# YTM32B1ME1 register map
Vendor: YTMicro; File version: 1.0
CPU: CM33 r0p4, little endian, MPU, FPU, 2 interrupt priority bits
Registers are 32-bit, read-write, reset 0x0 unless marked. A register's access mark holds for its fields unless they carry their own. Offsets are from the block's base; [hi:lo] are bit positions; {n}, {i} and the like mark numbered series; 'fields as' and 'values as' point back to an identical list.

## SCU — System Clock Unit of Microcontroller
Base 0x401F0000; register names take the prefix SCU_
0x00 CLKS — The register contains clock select bits.
  [1:0] CLKSRCSEL — System Clock Source selection bits.
    0=Select FIRC as system clock source; 1=Select PLL as system clock source; 2=Select FXOSC as system clock source; 3=Select SIRC as system clock source
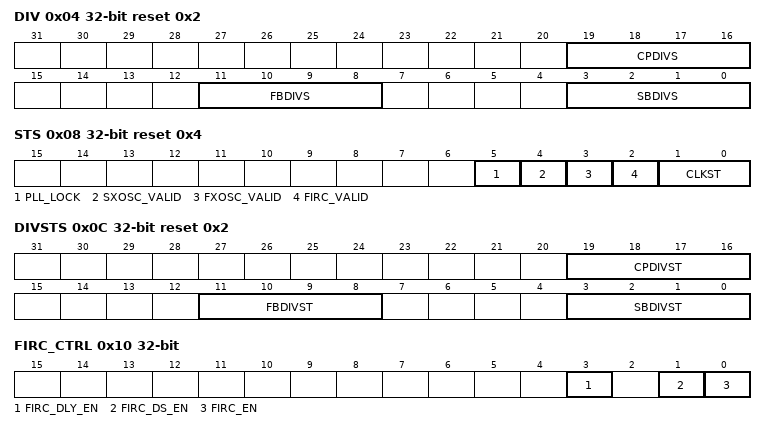
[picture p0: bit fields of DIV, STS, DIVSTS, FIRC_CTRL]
0x04 DIV reset 0x2 — System Clock Divider
  [all] fields
    {v}=Divide by {v+1} (v=0..15)
  [19:16] CPDIVS — Core Platform Clock Divider Value
  [11:8] FBDIVS — Fast Bus Clock Divider Value
  [3:0] SBDIVS — Slow Bus Clock Divider Value
0x08 STS ro reset 0x4 — System Clock Unit Status register
  [5] PLL_LOCK
    0=PLL unlocked; 1=PLL locked
  [4] SXOSC_VALID rw — Indicates SXOSC Clock is valid.
    0=SXOSC Clock invalid; 1=SXOSC Clock Valid
  [3] FXOSC_VALID rw — Indicates FXOSC Clock is valid.
    0=FXOSC Clock invalid; 1=FXOSC Clock valid
  [2] FIRC_VALID rw — Indicates FIRC Clock is valid.
    0=FIRC Clock invalid; 1=FIRC Clock valid
  [1:0] CLKST rw — Indicats System Clock Source Selection status.
    0=FIRC is selected as system clock source; 1=PLL is selected as system clock source; 2=FXOSC is selected as system clock source; 3=SIRC is selected as system clock source
0x0C DIVSTS ro reset 0x2 — System Clock Unit clock divider status
  [all] fields
    {v}=Divide by {v+1} (v=0..15)
  [19:16] CPDIVST rw — Core Platform Clock Divider Value
  [11:8] FBDIVST rw — Fast Bus Clock Divider Value
  [3:0] SBDIVST rw — Slow Bus Clock Divider Value
0x10 FIRC_CTRL — FIRC control register
  [3] FIRC_DLY_EN — Delay FIRC clock out.
    0=Disable FIRC clock out delay; 1=Enable FIRC clock out delay
  [1] FIRC_DS_EN — Enable FIRC when chip enters Deepsleep mode.
    0=Disable FIRC when chip enters Deepsleep mode; 1=Enable FIRC when chip enters Deepsleep mode
  [0] FIRC_EN — Enable FIRC regardless it is selected as system clock source.
    0=Disable FIRC if it is not selected as system clock source; 1=Enable FIRC regardless it is selected as system clock or not
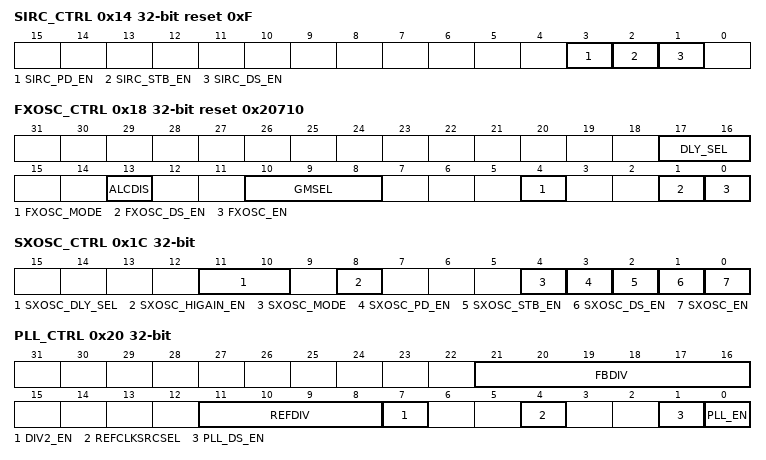
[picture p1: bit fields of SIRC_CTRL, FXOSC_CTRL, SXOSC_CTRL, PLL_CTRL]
0x14 SIRC_CTRL reset 0xF — SIRC control register
  [3] SIRC_PD_EN — Enable/Disable SIRC when chip enters Powerdown mode.
    0=Disable SIRC when chip enters Powerdown mode; 1=Enable SIRC when chip enters Powerdown mode
  [2] SIRC_STB_EN — Enable SIRC when chip enters Standby mode.
    0=Disable SIRC when chip enters Standby mode; 1=Enable SIRC when chip enters Standby mode
  [1] SIRC_DS_EN — Enable SIRC when chip enters Deepsleep mode.
    0=Disable SIRC when chip enters Deepsleep mode; 1=Enable SIRC when chip enters Deepsleep mode
0x18 FXOSC_CTRL reset 0x20710 — FXOSC control register
  [17:16] DLY_SEL — FXOSC clock output delay select.
    0=4096 cycles; 1=8192 cycles; 2=16384 cycles (default); 3=32768 cycles
  [13] ALCDIS — This bit should not be changed when FXOSC_VALID is high
  [10:8] GMSEL — FXOSC Gain Select for different oscillators
    1=used for 4MHz-6MHz oscillator; 2=used for 6MHz-8MHz oscillator; 3=used for 8MHz-12MHz oscillator; 5=used for 12MHz-20MHz oscillator; 6=used for 20MHz-32MHz oscillator; 7=used for 32MHz-40MHz oscillator
  [4] FXOSC_MODE — Select FXOSC oscillator mode or bypass mode
    0=FXOSC bypass mode; 1=FXOSC oscillator mode
  [1] FXOSC_DS_EN — Enable FXOSC when chip enters Deepsleep mode.
    0=Disable FXOSC when chip enters Deepsleep mode; 1=Enable FXOSC when chip enters Deepsleep mode
  [0] FXOSC_EN — Enable Fast crystal osc regardless it is selected as system clock source.
    0=Disable FXOSC if it is not selected as system clock source; 1=Enable FXOSC regardless it is selected as system clock or not
0x1C SXOSC_CTRL — SXOSC control register
  [11:10] SXOSC_DLY_SEL — SXOSC clock output delay select.
    0=1024 cycles (default); 1=2048 cycles; 2=4096 cycles; 3=8192 cycles
  [8] SXOSC_HIGAIN_EN — Enable/Disable SXOSC High Gain
    0=Disable SXOSC High Gain; 1=Enable SXOSC High Gain
  [4] SXOSC_MODE — Select SXOSC oscillator mode or bypass mode
    0=SXOSC bypass mode; 1=SXOSC oscillator mode
  [3] SXOSC_PD_EN — Enable/Disable SXOSC when chip enters Powerdown mode.
    0=Disable SXOSC when chip enters Standby mode; 1=Enable SXOSC when chip enters Standby mode
  [2] SXOSC_STB_EN — Enable SXOSC when chip enters Standby mode.
    values as SXOSC_PD_EN
  [1] SXOSC_DS_EN — Enable SXOSC when chip enters Deepsleep mode.
    0=Disable SXOSC when chip enters Deepsleep mode; 1=Enable SXOSC when chip enters Deepsleep mode
  [0] SXOSC_EN — Enable/Disable SXOSC
    0=Disable SXOSC; 1=Enable SXOSC
0x20 PLL_CTRL — System Clock Unit PLL control register, changes to this register should be done when PLL is disabled to prevent glitches to system clock source.
  [21:16] FBDIV — The FBDIV bits establish the value of the divider in th PLL feedabck loop. Please refer to \hyperref[phase-locked-loop-clockpll]{Phase-Locked Loop Clock(PLL)}.
  [11:8] REFDIV — Selects the amount to divide down the reference clock for the PLL. Please refer to \hyperref[phase-locked-loop-clockpll]{Phase-Locked Loop Clock(PLL)}.
  [7] DIV2_EN — Enable PLL output divided by 2
    0=PLL output not divided; 1=PLL output divided by 2
  [4] REFCLKSRCSEL — PLL reference clock source select bit
    0=Select FXOSC as PLL reference clock; 1=Select FIRC as PLL reference clock
  [1] PLL_DS_EN — Enable/Disable PLL when chip enters Deepsleep mode.
    0=Disable PLL when chip enters Deepsleep mode; 1=Enable PLL when chip enters Deepsleep mode
  [0] PLL_EN — Enable/Disable PLL regardless it is selected as system clock source.
    0=Disable PLL if it is not selected as system clock source; 1=Enable PLL regardless it is selected as system clock or not
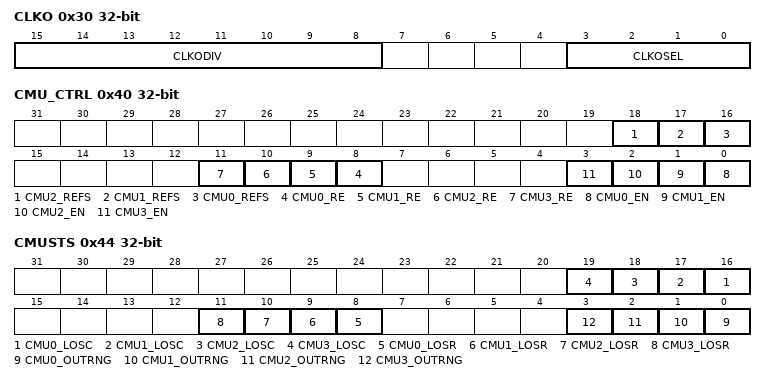
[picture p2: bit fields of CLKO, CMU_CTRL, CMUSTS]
0x30 CLKO — This register is to select the clock sources to output to chip IOs for external use.
  [15:8] CLKODIV — Clock output divider value. \begin{itemize}[label={}] \item 0b00000000 - DIV disable \item 0b00000001 - DIV disable \item 0b00000010 - DIV as the value \vspace*{-\baselineskip} \end{itemize}
  [3:0] CLKOSEL — Clock output source select
    0=None clock select to output; 1=FIRC clock output; 2=SIRC clock output; 3=FXOSC clock output; 4=SXOSC clock output; 5=PLL clock output; 6=TRNG oscillator clock output; 7=Core clock output; 8=LPO clock output
0x40 CMU_CTRL — System Clock Unit Clock Monitor Unit control register
  [18] CMU2_REFS — Select reference clock of CMU2
    0=SIRC selected as reference clock of CMU; 1=FXOSC selected as reference clock of CMU
  [17] CMU1_REFS — Select reference clock of CMU1
    values as CMU2_REFS
  [16] CMU0_REFS — Select reference clock of CMU0
    values as CMU2_REFS
  [n+8] CMU{n}_RE (n=0..3) — Enable/Disable reset when CMU{n} event happens
    0=Reset disable when CMU event happens; 1=Reset enable when CMU event happens
  [n] CMU{n}_EN (n=0..3) — Enable/Disable CMU{n}
    0=CMU disable; 1=CMU enable
0x44 CMUSTS — System Clock Unit Clock Monitor Unit status register
  [n+16] CMU{n}_LOSC (n=0..3) — Indicates CMU{n} loss of clock event
    0=Checked Clock of CMU{n} is available; 1=Checked Clock of CMU{n} is lost
  [n+8] CMU{n}_LOSR (n=0..3) — Indicates CMU{n} loss of reference clock event
    0=Reference Clock of CMU{n} is available; 1=Reference Clock of CMU{n} is lost
  [n] CMU{n}_OUTRNG (n=0..3) — Indicates Checked Clock of CMU{n} is out of range
    0=Checked Clock of CMU{n} is out of range; 1=Reference Clock of CMU{n} is lost
{0x48+8i} CMUCMP{i}_HIGH reset 0xFFFF (i=0..3) — System Clock Unit Clock Monitor High Comparison Value Register
  [15:0] VAL
{0x4C+8i} CMUCMP{i}_LOW (i=0..3) — System Clock Unit Clock Monitor Low Comparison Value Register
  [15:0] VAL
